# PBIST register map
Vendor: Texas Instruments
Peripheral module from a debugger description file (folder xwrl64xx).
Registers are 32-bit, read-write, no defined reset value unless marked. A register's access mark holds for its fields unless they carry their own. Offsets are as the file gives them; lines under a group give offsets from that group; [hi:lo] are bit positions; {n}, {i} and the like mark numbered series; 'fields as' and 'values as' point back to an identical list; <NAME> marks a mode.

## PBIST
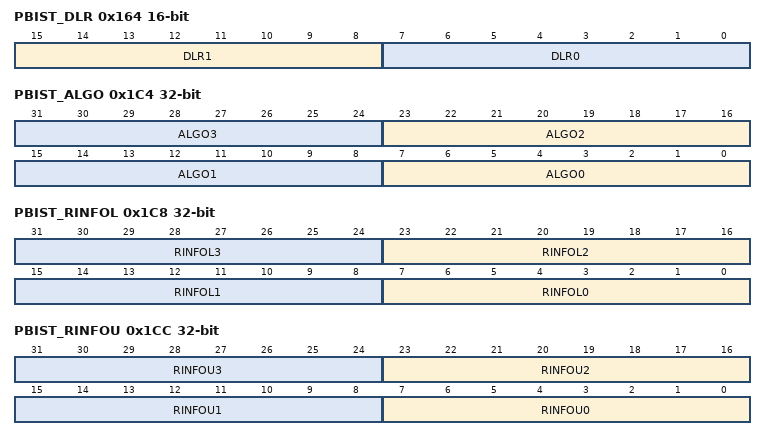
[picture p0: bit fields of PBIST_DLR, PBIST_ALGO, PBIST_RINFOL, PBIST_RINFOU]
0x164 PBIST_DLR 16-bit — Datalogger 0
  [15:8] DLR1 — Datalogger Register [8] : Reserevd [9] : Default Testing Mode. When in this mode, ROM-based testing is kicked off. If the intention is to perform go/no-go testing via config, write to both this bit and bit [2] of the Datalogger Register simultaneously [15:10] : Reserevd
  [7:0] DLR0 — Datalogger Register [1:0] : Reserved [2] : ROM-based testing mode. Setting this bit to 1 enables the PBIST controller to execute test algorithms that are stored in the PBIST ROM [3] : Do not change this bit from its default value of 1 [4] : Config access mode. Setting this bit allows the host processor to configure the PBIST controller registers [7:5] : Reserved
0x16C PBIST_PC 5-bit — Program Control
  [4:0] PBIST_PC — TI Internal Register.Reserved for HW RnD
0x180 PBIST_PACT 1-bit — Pbist Active
  [0] PBIST_PACT — Pbist Active/ROM Clock Enable Register [0]: This bit must be set to turn on internal PBIST clocks. Setting this bit asserts an internal signal that is used as the clock gate enable. As long as this bit is 0, any access to PBIST will not go through, and PBIST will remain in an almost zero-power mode. Value 0 = Disable internal PBIST clocks Value 1 = Enable internal PBIST clocks
0x188 PBIST_OVR 4-bit — PBIST Overrides
  [3:0] PBIST_OVR — TI Internal Register.Reserved for HW RnD
0x190 PBIST_FSFR0 ro — Fail status fail - port 0
  [0] PBIST_FSFR0 — Fail Status Fail Register- Port 0 This register indicates if a failure occurred during a memory self-test. Value 0 = No failure occurred Value 1 = Indicates a failure
0x194 PBIST_FSFR1 ro — Fail status fail - port 1
  [0] PBIST_FSFR1 — Fail Status Fail Register- Port 1 This register indicates if a failure occurred during a memory self-test. Value 0 = No failure occurred Value 1 = Indicates a failure
0x1C0 PBIST_ROM 2-bit — Rom Mask
  [1:0] PBIST_ROM — Rom Mask . This two-bit register sets appropriate ROM access modes for the PBIST controller. Value 0h = No information is used from ROM Value 1h = Only RAM Group information from ROM Vaule 2h = Only Algorithm information from ROM Value 3h = Both Algorithm and RAM information from ROM. This option should be selected for application self-test.
0x1C4 PBIST_ALGO — ROM Algorithm Mask 0
  [8n+7:8n] ALGO{n} (n=0..3) — This register is used to indicate the algorithm(s) to be used for the memory self-test routine. Each bit corresponds to a specific algorithm. Writing a value 1 to the particular bit, enables the corresponding algorithm. Writing a value 0 to the particular bit, disables the corresponding algorithm.
0x1C8 PBIST_RINFOL — RAM Info Mask Lower 0
  [8n+7:8n] RINFOL{n} (n=0..3) — This register is to select memory groups to run the algorithms selected in the PBIST_ALGO register. For an algorithmto be executed on a particular memory group, the corresponding bit in this register must be set to 1. The default value of this register is all 1s, which means all the memory groups are selected. Writing a value 0 to the particular bit, disables the corresponding memory group.
0x1CC PBIST_RINFOU — RAM Info Mask Upper 0
  [8n+7:8n] RINFOU{n} (n=0..3) — This register is to select memory groups to run the algorithms selected in the PBIST_ALGO register. For an algorithmto be executed on a particular memory group, the corresponding bit in this register must be set to 1. The default value of this register is all 1s, which means all the memory groups are selected. Writing a value 0 to the particular bit, disables the corresponding memory group.
